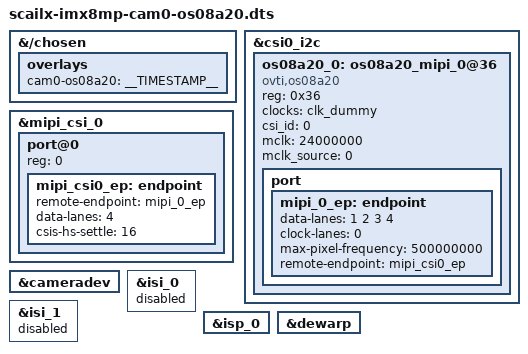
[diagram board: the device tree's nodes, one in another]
// SPDX-License-Identifier: (GPL-2.0 OR MIT)
/*
 * Copyright (C) 2023 VideologyInc
 *
 */

/dts-v1/;
/plugin/;

#include <dt-bindings/clock/imx8mp-clock.h>
#include <dt-bindings/gpio/gpio.h>

&{/chosen} {
	overlays {
		cam0-os08a20 = __TIMESTAMP__;
	};
};

&csi0_i2c {
	os08a20_0: os08a20_mipi_0@36 {
		compatible = "ovti,os08a20";
		reg = <0x36>;
		clocks = <&clk_dummy>;
		clock-names = "csi_mclk";
		csi_id = <0>;
		mclk = <24000000>;
		mclk_source = <0>;
		status = "okay";
		// rst-gpios = <&gpio_expander 9 GPIO_ACTIVE_LOW>;
		// pwn-gpios = <&gpio_expander 0 GPIO_ACTIVE_HIGH>;

		port {
			mipi_0_ep: endpoint {
				data-lanes = <1 2 3 4>;
				clock-lanes = <0>;
				max-pixel-frequency = /bits/ 64 <500000000>;
				remote-endpoint = <&mipi_csi0_ep>;
			};
		};

	};
};

&mipi_csi_0 {
	status = "okay";

	port@0 {
		reg = <0>;
		mipi_csi0_ep: endpoint {
			remote-endpoint = <&mipi_0_ep>;
			data-lanes = <4>;
			csis-hs-settle = <16>;
		};
	};
};

&cameradev {
	status = "okay";
};

&isi_0 {
	status = "disabled";
};

&isi_1 {
	status = "disabled";
};

&isp_0 {
	status = "okay";
};

&dewarp {
	status = "okay";
};
